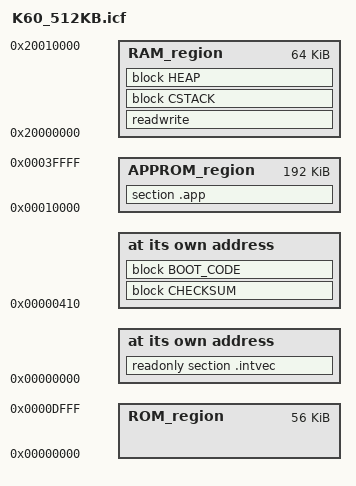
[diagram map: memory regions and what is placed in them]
/*###ICF### Section handled by ICF editor, don't touch! ****/
/*-Editor annotation file-*/
/* IcfEditorFile="$TOOLKIT_DIR$\config\ide\IcfEditor\cortex_v1_0.xml" */
/*-Specials-*/
define symbol __ICFEDIT_intvec_start__ = 0x00000000;
/*-Memory Regions-*/
define symbol __ICFEDIT_region_ROM_start__ = 0x00000000;
define symbol __ICFEDIT_region_ROM_end__   = 0x0000DFFF;
define symbol __ICFEDIT_region_RAM_start__ = 0x20000000;
define symbol __ICFEDIT_region_RAM_end__   = 0x20010000;
/*-Sizes-*/
define symbol __ICFEDIT_size_cstack__ = 0x1000;
define symbol __ICFEDIT_size_heap__   = 0x800;
/**** End of ICF editor section. ###ICF###*/

define symbol __APP_ROM_START = 0x10000;
define symbol __APP_ROM_END = 0x3FFFF;

//define symbol __region_RAM2_start__ = 0x20000000;
//define symbol __region_RAM2_end__ = 0x20010000;

define symbol __FlashConfig_start__ = 0x00000400;
define symbol __FlashConfig_end__ = 0x0000040f;

define exported symbol __VECTOR_TABLE = 0x00000000;
define exported symbol __VECTOR_RAM = 0x1fff0000;

define exported symbol __BOOT_STACK_ADDRESS = __ICFEDIT_region_RAM_end__ - 8;	//0x2000FFF8;

define symbol __code_start__ = 0x00000410;

//
// Define a memory region that covers the entire 4 GB addressible space of the
// processor.
//
define memory mem with size = 4G;
define region ROM_region   = mem:[from __ICFEDIT_region_ROM_start__   to __ICFEDIT_region_ROM_end__];
//define region ROM_region = mem:[from __ICFEDIT_region_ROM_start__ to (__FlashConfig_start__ - 1)] | mem:[from (__FlashConfig_end__+1)  to __ICFEDIT_region_ROM_end__];
define region RAM_region   = mem:[from __ICFEDIT_region_RAM_start__   to __ICFEDIT_region_RAM_end__];
//define region RAM_region   = mem:[from __region_RAM2_start__ to __region_RAM2_end__];

define region APPROM_region = mem:[from __APP_ROM_START to __APP_ROM_END];

define block CSTACK with alignment = 8, size = __ICFEDIT_size_cstack__   { };
define block HEAP with alignment = 8, size = __ICFEDIT_size_heap__     { };





//
// Indicate that the read/write values should be initialized by copying from
// flash.
//
initialize by copy { readwrite };
//initialize manually { readwrite };
initialize manually { section .data};
initialize manually { section .textrw };
do not initialize  { section .noinit };
define block CHECKSUM { ro section .checksum_main };
//define block CodeRelocate { section .textrw_init };
//define block CodeRelocateRam { section .textrw };

//
// Place the interrupt vectors at the start of flash.
//
place at address mem:__ICFEDIT_intvec_start__ { readonly section .intvec };
//place at address mem:__code_start__ { readonly section .noinit };

define block BOOT_CODE with alignment = 4, fixed order
{

  ro object head.o,
  ro, 
  ro data,
  ro section checksum_end_mark,

};

place at address mem:__code_start__ { block CHECKSUM, block BOOT_CODE };

//
// Place all read only items into ROM.
//
//place in ROM_region   {readonly};


//
// Place all read/write items into RAM.
//
place in RAM_region   { readwrite, block CSTACK, block HEAP };
                        
//"CHECKSUM":
//place at end of ROM_region { ro section .checksum_main };
//place in ROM_region { ro, last block CHECKSUM };
//keep { section .checksum_main };

place in APPROM_region {section .app};

 
 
